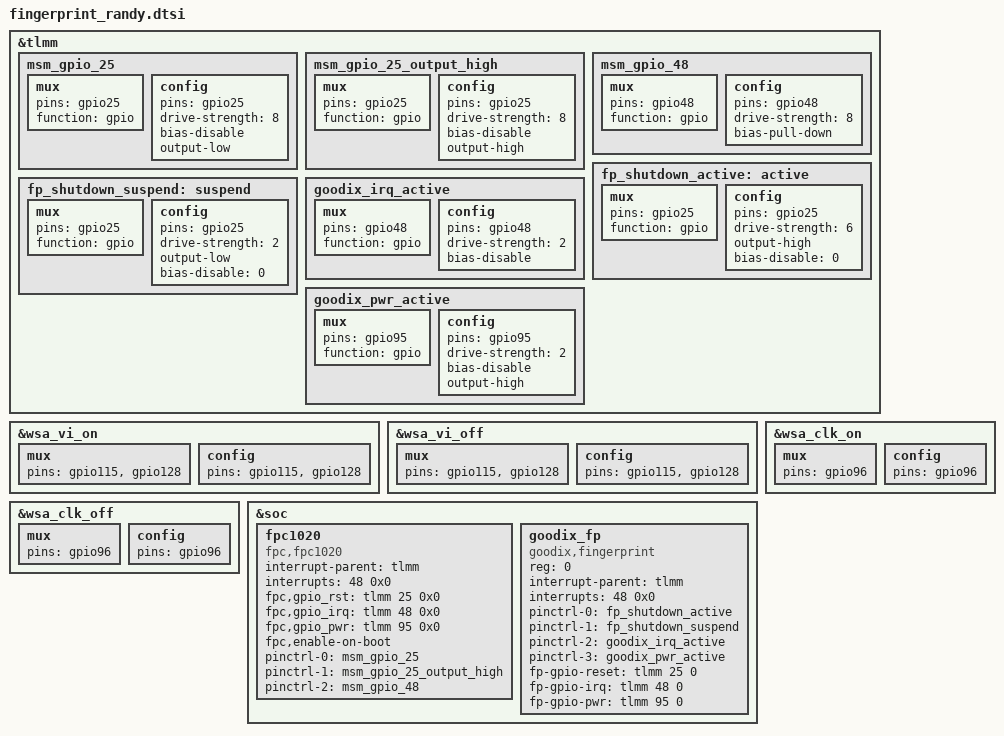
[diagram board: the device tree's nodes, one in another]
/*for fingerprint config*/
&tlmm {
	msm_gpio_25: msm_gpio_25{
		mux {
			pins = "gpio25";
			function = "gpio";
		};

		config {
			pins = "gpio25";
			drive-strength = <8>;
			bias-disable;
			output-low;
		};
	};
	msm_gpio_25_output_high: msm_gpio_25_output_high {
		mux {
			pins = "gpio25";
			function = "gpio";
		};

		config {
			pins = "gpio25";
			drive-strength = <8>;
			bias-disable;
			output-high;
		};
	};

	msm_gpio_48: msm_gpio_48 {
		mux {
			pins = "gpio48";
			function = "gpio";
		};

		config {
			pins = "gpio48";
			drive-strength = <8>;
			bias-pull-down;
		};
	};
	fp_shutdown_active:active{
		mux{
			pins = "gpio25";
			function = "gpio";
		};
		config{
			pins = "gpio25";
			drive-strength = <6>;
			output-high;
			bias-disable = <0>;
		};
	};

	fp_shutdown_suspend:suspend{
		mux{
			pins = "gpio25";
			function = "gpio";
		};
		config{
			pins = "gpio25";
			drive-strength = <2>;
			output-low;
			bias-disable = <0>;
		};
	};

	goodix_irq_active: goodix_irq_active{
		mux{
			pins = "gpio48";
			function = "gpio";
		};
		config{
			pins = "gpio48";
			drive-strength = <2>;
			bias-disable; /* No PULL */
		};
	};
	goodix_pwr_active: goodix_pwr_active {
		mux{
			pins = "gpio95";
			function = "gpio";
		};
		config {
			pins = "gpio95";
			drive-strength = <2>;
			bias-disable;
			output-high;
		};
	};
};

/*add  GPIO config different from platform begin  */
&wsa_vi_on {
	mux {
		pins = "gpio115", "gpio128";
	};

	config {
		pins = "gpio115", "gpio128";
	};
};

&wsa_vi_off {
	mux {
		pins = "gpio115", "gpio128";
	};

	config {
		pins = "gpio115", "gpio128";
	};
};
&wsa_clk_on {
	mux {
		pins = "gpio96";
	};

	config {
		pins = "gpio96";
	};
};

&wsa_clk_off {
	mux {
		pins = "gpio96";
	};

	config {
		pins = "gpio96";
	};
};
/*end*/

&soc {
	fpc1020 {
		status = "ok";
		compatible = "fpc,fpc1020";
		interrupt-parent = <&tlmm>;
		interrupts = <48 0x0>;
		fpc,gpio_rst	= <&tlmm 25 0x0>;
		fpc,gpio_irq	= <&tlmm 48 0x0>;
		fpc,gpio_pwr	= <&tlmm 95 0x0>;
		fpc,enable-on-boot;
		/*fpc,enable-wakeup; */

		pinctrl-names = "fpc1020_reset_reset",
		"fpc1020_reset_active",
		"fpc1020_irq_active";

		pinctrl-0 = <&msm_gpio_25>;
		pinctrl-1 = <&msm_gpio_25_output_high>;
		pinctrl-2 = <&msm_gpio_48>;
	};
	goodix_fp {
		status = "ok";
		reg = <0>;
		compatible = "goodix,fingerprint";
		interrupt-parent = <&tlmm>;
		interrupts = <48 0x0>;

		pinctrl-names = "goodix_active", "goodix_suspend", "goodix_irq", "pwr_active";
		pinctrl-0 = <&fp_shutdown_active>;
		pinctrl-1 = <&fp_shutdown_suspend>;
		pinctrl-2 = <&goodix_irq_active>;
		pinctrl-3 = <&goodix_pwr_active>;

		fp-gpio-reset = <&tlmm 25 0>;
		fp-gpio-irq = <&tlmm 48 0>;
		fp-gpio-pwr = <&tlmm 95 0>;
		interrupt-names = "goodix_wake_up";
	};
};


